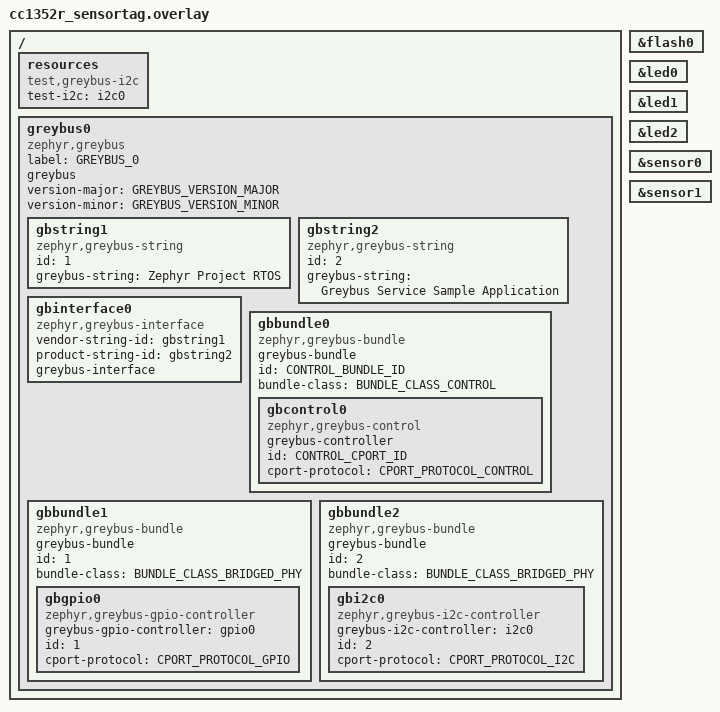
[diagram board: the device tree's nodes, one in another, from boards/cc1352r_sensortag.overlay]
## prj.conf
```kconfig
CONFIG_HEAP_MEM_POOL_SIZE=16384
CONFIG_NET_HOSTNAME_ENABLE=y
CONFIG_DNS_SD=y
CONFIG_NEWLIB_LIBC=y

# Greybus options
CONFIG_GREYBUS=y
CONFIG_GREYBUS_CONTROL=y

# Console options
CONFIG_CONSOLE_SUBSYS=y
CONFIG_CONSOLE_GETCHAR=y

# Generic networking options
CONFIG_NETWORKING=y
CONFIG_NET_UDP=y
CONFIG_NET_TCP=y
CONFIG_NET_IPV6=y
CONFIG_NET_IPV4=y
CONFIG_NET_SOCKETS=y
CONFIG_NET_SOCKETS_POSIX_NAMES=y
CONFIG_NET_SOCKETS_POLL_MAX=16
CONFIG_POSIX_MAX_FDS=16
CONFIG_NET_CONNECTION_MANAGER=y
CONFIG_NET_MAX_CONN=16

# Service advertisement options
CONFIG_MDNS_RESPONDER=y
CONFIG_MDNS_RESPONDER_DNS_SD=y

# Kernel options
CONFIG_MAIN_STACK_SIZE=1024
CONFIG_ENTROPY_GENERATOR=y
CONFIG_INIT_STACKS=y

# Logging
CONFIG_NET_LOG=y
CONFIG_LOG=y
CONFIG_NET_STATISTICS=y
CONFIG_PRINTK=y

# Network buffers
CONFIG_NET_PKT_RX_COUNT=16
CONFIG_NET_PKT_TX_COUNT=16
CONFIG_NET_BUF_RX_COUNT=16
CONFIG_NET_BUF_TX_COUNT=16
CONFIG_NET_CONTEXT_NET_PKT_POOL=y

# IP address options
CONFIG_NET_IF_UNICAST_IPV6_ADDR_COUNT=3
CONFIG_NET_IF_MCAST_IPV6_ADDR_COUNT=4
CONFIG_NET_MAX_CONTEXTS=16

# Network shell
CONFIG_NET_SHELL=y
CONFIG_SHELL=y

# Network application options and configuration
CONFIG_NET_CONFIG_SETTINGS=y
CONFIG_NET_CONFIG_MY_IPV6_ADDR="2001:db8::1"
CONFIG_NET_CONFIG_PEER_IPV6_ADDR="2001:db8::2"
CONFIG_NET_CONFIG_MY_IPV4_ADDR="192.0.2.1"
CONFIG_NET_CONFIG_PEER_IPV4_ADDR="192.0.2.2"

# Pthread options
CONFIG_MAX_PTHREAD_COUNT=16

CONFIG_GREYBUS_LOG_LEVEL_DBG=y
```

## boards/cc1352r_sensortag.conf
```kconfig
CONFIG_GPIO=y
CONFIG_GREYBUS_GPIO=y

CONFIG_I2C=y
CONFIG_GREYBUS_I2C=y

CONFIG_SPI=y
CONFIG_SPI_0=y
CONFIG_GREYBUS_SPI=y

# useful for verifying functionality with SPI
CONFIG_SENSOR=y
CONFIG_ADXL362=y
CONFIG_SENSOR_SHELL=y

# useful for verifying functionality with I2C
CONFIG_OPT3001=y
```

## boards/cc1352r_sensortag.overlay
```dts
/*
 * Copyright (c) 2020 Friedt Professional Engineering Services, Inc
 *
 * SPDX-License-Identifier: Apache-2.0
 */
 #include <dt-bindings/greybus/greybus.h>
 #include <dt-bindings/greybus/spi.h>

/ {
	resources {
		compatible = "test,greybus-i2c";
		test-i2c = <&i2c0>; 
	};

	greybus0: greybus0 {
		compatible = "zephyr,greybus";
		label = "GREYBUS_0";
		greybus;
	};
};

&flash0 {
	status = "okay";
};

&led0 {
	status = "okay";
};

&led1 {
	status = "okay";
};

&led2 {
	status = "okay";
};

&sensor0 {
	status = "okay";
};

&sensor1 {
	status = "okay";
};

&greybus0 {
	status = "okay";
	/* defaults in effect, so this isn't necessary */
	version-major = <GREYBUS_VERSION_MAJOR>;
	version-minor = <GREYBUS_VERSION_MINOR>;

	gbstring1: gbstring1 {
		status = "okay";
		compatible = "zephyr,greybus-string";
		/* NB: string id 0 is invalid */
		id = <1>;
		greybus-string = "Zephyr Project RTOS";
	};

	gbstring2: gbstring2 {
		status = "okay";
		compatible = "zephyr,greybus-string";
		id = <2>;
		greybus-string = "Greybus Service Sample Application";
	};

	gbinterface0 {
		status = "okay";
		compatible = "zephyr,greybus-interface";
		vendor-string-id = <&gbstring1>;
		product-string-id = <&gbstring2>;
		greybus-interface;
	};

	gbbundle0 {
		status = "okay";
		compatible = "zephyr,greybus-bundle";
		greybus-bundle;
		/* Control Bundle 0
		 * Note: control bundle 0 and control cport 0 are optional
		 * Since instance numbers automatically begin at 0, the id
		 * is a mandatory field for bundles and cports.
		 */
		id = <CONTROL_BUNDLE_ID>;
		bundle-class = <BUNDLE_CLASS_CONTROL>;

		gbcontrol0 {
			status = "okay";
			compatible = "zephyr,greybus-control";
			greybus-controller;
			/* Control CPort 0
			 * Note: control bundle 0 and control cport 0 are optional
			 * Since instance numbers automatically begin at 0, the id
			 * is a mandatory field for bundles and cports.
			 */
			id = <CONTROL_CPORT_ID>;
			cport-protocol = <CPORT_PROTOCOL_CONTROL>; 
		};
	};

	gbbundle1 {
		status = "okay";
		compatible = "zephyr,greybus-bundle";
		greybus-bundle;
		id = <1>;
		bundle-class = <BUNDLE_CLASS_BRIDGED_PHY>;		
				
		gbgpio0 {
			status = "okay";
			compatible = "zephyr,greybus-gpio-controller";
			greybus-gpio-controller = <&gpio0>;
			/* GPIO is CPort 1 in this case */
			id = <1>;
			cport-protocol = <CPORT_PROTOCOL_GPIO>;
		};
	};
	
	gbbundle2 {
		status = "okay";
		compatible = "zephyr,greybus-bundle";
		greybus-bundle;
		id = <2>;
		bundle-class = <BUNDLE_CLASS_BRIDGED_PHY>;		
				
		gbi2c0 {
			status = "okay";
			compatible = "zephyr,greybus-i2c-controller";
			greybus-i2c-controller = <&i2c0>;
			/* I2C is CPort 2 in this case */
			id = <2>;
			cport-protocol = <CPORT_PROTOCOL_I2C>;
		};
	};
};
```

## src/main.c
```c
/*
 * Copyright (c) 2109 Friedt Professional Engineering Services, Inc
 *
 * SPDX-License-Identifier: Apache-2.0
 */

#include <zephyr.h>

int main(int argc, char *argv[])
{
	for(;;) {
		k_usleep(1000000);
	}

	return 0;
}
```
